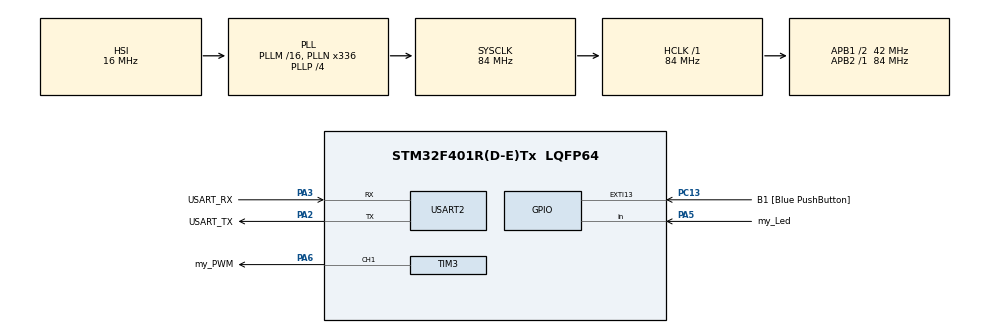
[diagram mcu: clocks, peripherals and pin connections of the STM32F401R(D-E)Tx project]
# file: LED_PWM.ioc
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Mcu.Family=STM32F4
Mcu.Name=STM32F401R(D-E)Tx
Mcu.Package=LQFP64
NVIC.PriorityGroup=NVIC_PRIORITYGROUP_0
PA13.GPIO_Label=TMS
PA13.Mode=Serial_Wire
PA13.Signal=SYS_JTMS-SWDIO
PA14.GPIO_Label=TCK
PA14.Mode=Serial_Wire
PA14.Signal=SYS_JTCK-SWCLK
PA2.GPIO_Label=USART_TX
PA2.GPIO_Mode=GPIO_MODE_AF_PP
PA2.GPIO_PuPd=GPIO_NOPULL
PA2.GPIO_Speed=GPIO_SPEED_FREQ_LOW
PA2.Mode=Asynchronous
PA2.Signal=USART2_TX
PA3.GPIO_Label=USART_RX
PA3.GPIO_Mode=GPIO_MODE_AF_PP
PA3.GPIO_PuPd=GPIO_NOPULL
PA3.GPIO_Speed=GPIO_SPEED_FREQ_LOW
PA3.Mode=Asynchronous
PA3.Signal=USART2_RX
PA5.GPIO_Label=my_Led
PA5.Signal=GPIO_Input
PA6.GPIO_Label=my_PWM
PA6.Signal=S_TIM3_CH1
PB3.GPIO_Label=SWO
PB3.Signal=SYS_JTDO-SWO
PC13-ANTI_TAMP.GPIO_Label=B1 [Blue PushButton]
PC13-ANTI_TAMP.GPIO_ModeDefaultEXTI=GPIO_MODE_IT_FALLING
PC13-ANTI_TAMP.GPIO_PuPd=GPIO_NOPULL
PC13-ANTI_TAMP.Signal=GPXTI13
PC14-OSC32_IN.Mode=LSE-External-Oscillator
PC14-OSC32_IN.Signal=RCC_OSC32_IN
PC15-OSC32_OUT.Mode=LSE-External-Oscillator
PC15-OSC32_OUT.Signal=RCC_OSC32_OUT
PH0\ -\ OSC_IN.Mode=HSE-External-Clock-Source
PH0\ -\ OSC_IN.Signal=RCC_OSC_IN
PH1\ -\ OSC_OUT.Mode=HSE-External-Clock-Source
PH1\ -\ OSC_OUT.Signal=RCC_OSC_OUT
ProjectManager.HeapSize=0x200
ProjectManager.StackSize=0x400
ProjectManager.TargetToolchain=SW4STM32
RCC.48MHZClocksFreq_Value=48000000
RCC.AHBFreq_Value=84000000
RCC.APB1CLKDivider=RCC_HCLK_DIV2
RCC.APB1Freq_Value=42000000
RCC.APB1TimFreq_Value=84000000
RCC.APB2Freq_Value=84000000
RCC.APB2TimFreq_Value=84000000
RCC.CortexFreq_Value=84000000
RCC.HCLKFreq_Value=84000000
RCC.HSE_VALUE=8000000
RCC.HSI_VALUE=16000000
RCC.PLLN=336
RCC.PLLP=RCC_PLLP_DIV4
RCC.PLLQ=7
RCC.SYSCLKFreq_VALUE=84000000
RCC.SYSCLKSource=RCC_SYSCLKSOURCE_PLLCLK
RCC.VCOOutputFreq_Value=336000000
SH.S_TIM3_CH1.0=TIM3_CH1,PWM Generation1 CH1
TIM3.Channel-PWM\ Generation1\ CH1=TIM_CHANNEL_1
TIM3.Period=100
TIM3.Prescaler=84
USART2.VirtualMode=VM_ASYNC
VP_TIM3_VS_ClockSourceINT.Mode=Internal
board=NUCLEO-F401RE

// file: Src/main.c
/**
  ******************************************************************************
  * @file           : main.c
  * @brief          : Main program body
  ******************************************************************************
  ** This notice applies to any and all portions of this file
  * that are not between comment pairs USER CODE BEGIN and
  * USER CODE END. Other portions of this file, whether
  * inserted by the user or by software development tools
  * are owned by their respective copyright owners.
  *
  * COPYRIGHT(c) 2018 STMicroelectronics
  *
  * Redistribution and use in source and binary forms, with or without modification,
  * are permitted provided that the following conditions are met:
  *   1. Redistributions of source code must retain the above copyright notice,
  *      this list of conditions and the following disclaimer.
  *   2. Redistributions in binary form must reproduce the above copyright notice,
  *      this list of conditions and the following disclaimer in the documentation
  *      and/or other materials provided with the distribution.
  *   3. Neither the name of STMicroelectronics nor the names of its contributors
  *      may be used to endorse or promote products derived from this software
  *      without specific prior written permission.
  *
  * THIS SOFTWARE IS PROVIDED BY THE COPYRIGHT HOLDERS AND CONTRIBUTORS "AS IS"
  * AND ANY EXPRESS OR IMPLIED WARRANTIES, INCLUDING, BUT NOT LIMITED TO, THE
  * IMPLIED WARRANTIES OF MERCHANTABILITY AND FITNESS FOR A PARTICULAR PURPOSE ARE
  * DISCLAIMED. IN NO EVENT SHALL THE COPYRIGHT HOLDER OR CONTRIBUTORS BE LIABLE
  * FOR ANY DIRECT, INDIRECT, INCIDENTAL, SPECIAL, EXEMPLARY, OR CONSEQUENTIAL
  * DAMAGES (INCLUDING, BUT NOT LIMITED TO, PROCUREMENT OF SUBSTITUTE GOODS OR
  * SERVICES; LOSS OF USE, DATA, OR PROFITS; OR BUSINESS INTERRUPTION) HOWEVER
  * CAUSED AND ON ANY THEORY OF LIABILITY, WHETHER IN CONTRACT, STRICT LIABILITY,
  * OR TORT (INCLUDING NEGLIGENCE OR OTHERWISE) ARISING IN ANY WAY OUT OF THE USE
  * OF THIS SOFTWARE, EVEN IF ADVISED OF THE POSSIBILITY OF SUCH DAMAGE.
  *
  ******************************************************************************
  */
#include "main.h"
#include "stm32f4xx_hal.h"

TIM_HandleTypeDef htim3;

UART_HandleTypeDef huart2;

/* USER CODE BEGIN PV */
/* Private variables ---------------------------------------------------------*/

/* USER CODE END PV */

void SystemClock_Config(void);
static void MX_GPIO_Init(void);
static void MX_USART2_UART_Init(void);
static void MX_TIM3_Init(void);
void HAL_TIM_MspPostInit(TIM_HandleTypeDef *htim);

/* USER CODE BEGIN PFP */
/* Private function prototypes -----------------------------------------------*/

/* USER CODE END PFP */

int main(void)
{

  /* MCU Configuration----------------------------------------------------------*/

  /* Reset of all peripherals, Initializes the Flash interface and the Systick. */
  HAL_Init();

  /* Configure the system clock */
  SystemClock_Config();

  /* Initialize all configured peripherals */
  MX_GPIO_Init();
  MX_USART2_UART_Init();
  MX_TIM3_Init();
  /* USER CODE BEGIN 2 */

  HAL_TIM_PWM_Start(&htim3, TIM_CHANNEL_1);

  /* USER CODE END 2 */

  /* Infinite loop */
  while (1)
  {

  /* USER CODE BEGIN 3 */

	  unsigned short int pwm = 0;
	  __HAL_TIM_SET_COMPARE(&htim3, TIM_CHANNEL_1, 10);
	  for(pwm = 0; pwm < (unsigned short int)(htim3.Instance->ARR & 0x0000FFFF); pwm++){
		  __HAL_TIM_SET_COMPARE(&htim3, TIM_CHANNEL_1, pwm);
		  HAL_Delay(10);
	  }
	  for(pwm = (unsigned short int)(htim3.Instance->ARR & 0x0000FFFF); pwm > 0; pwm--){
		  __HAL_TIM_SET_COMPARE(&htim3, TIM_CHANNEL_1, pwm);
		  HAL_Delay(10);
	  }

  }
  /* USER CODE END 3 */

}

void SystemClock_Config(void)
{

  RCC_OscInitTypeDef RCC_OscInitStruct;
  RCC_ClkInitTypeDef RCC_ClkInitStruct;

    /**Configure the main internal regulator output voltage
    */
  __HAL_RCC_PWR_CLK_ENABLE();

  __HAL_PWR_VOLTAGESCALING_CONFIG(PWR_REGULATOR_VOLTAGE_SCALE2);

    /**Initializes the CPU, AHB and APB busses clocks
    */
  RCC_OscInitStruct.OscillatorType = RCC_OSCILLATORTYPE_HSI;
  RCC_OscInitStruct.HSIState = RCC_HSI_ON;
  RCC_OscInitStruct.HSICalibrationValue = 16;
  RCC_OscInitStruct.PLL.PLLState = RCC_PLL_ON;
  RCC_OscInitStruct.PLL.PLLSource = RCC_PLLSOURCE_HSI;
  RCC_OscInitStruct.PLL.PLLM = 16;
  RCC_OscInitStruct.PLL.PLLN = 336;
  RCC_OscInitStruct.PLL.PLLP = RCC_PLLP_DIV4;
  RCC_OscInitStruct.PLL.PLLQ = 7;
  if (HAL_RCC_OscConfig(&RCC_OscInitStruct) != HAL_OK)
  {
    _Error_Handler(__FILE__, __LINE__);
  }

    /**Initializes the CPU, AHB and APB busses clocks
    */
  RCC_ClkInitStruct.ClockType = RCC_CLOCKTYPE_HCLK|RCC_CLOCKTYPE_SYSCLK
                              |RCC_CLOCKTYPE_PCLK1|RCC_CLOCKTYPE_PCLK2;
  RCC_ClkInitStruct.SYSCLKSource = RCC_SYSCLKSOURCE_PLLCLK;
  RCC_ClkInitStruct.AHBCLKDivider = RCC_SYSCLK_DIV1;
  RCC_ClkInitStruct.APB1CLKDivider = RCC_HCLK_DIV2;
  RCC_ClkInitStruct.APB2CLKDivider = RCC_HCLK_DIV1;

  if (HAL_RCC_ClockConfig(&RCC_ClkInitStruct, FLASH_LATENCY_2) != HAL_OK)
  {
    _Error_Handler(__FILE__, __LINE__);
  }

    /**Configure the Systick interrupt time
    */
  HAL_SYSTICK_Config(HAL_RCC_GetHCLKFreq()/1000);

    /**Configure the Systick
    */
  HAL_SYSTICK_CLKSourceConfig(SYSTICK_CLKSOURCE_HCLK);

  /* SysTick_IRQn interrupt configuration */
  HAL_NVIC_SetPriority(SysTick_IRQn, 0, 0);
}

/* TIM3 init function */
static void MX_TIM3_Init(void)
{

  TIM_ClockConfigTypeDef sClockSourceConfig;
  TIM_MasterConfigTypeDef sMasterConfig;
  TIM_OC_InitTypeDef sConfigOC;

  htim3.Instance = TIM3;
  htim3.Init.Prescaler = 84;
  htim3.Init.CounterMode = TIM_COUNTERMODE_UP;
  htim3.Init.Period = 100;
  htim3.Init.ClockDivision = TIM_CLOCKDIVISION_DIV1;
  if (HAL_TIM_Base_Init(&htim3) != HAL_OK)
  {
    _Error_Handler(__FILE__, __LINE__);
  }

  sClockSourceConfig.ClockSource = TIM_CLOCKSOURCE_INTERNAL;
  if (HAL_TIM_ConfigClockSource(&htim3, &sClockSourceConfig) != HAL_OK)
  {
    _Error_Handler(__FILE__, __LINE__);
  }

  if (HAL_TIM_PWM_Init(&htim3) != HAL_OK)
  {
    _Error_Handler(__FILE__, __LINE__);
  }

  sMasterConfig.MasterOutputTrigger = TIM_TRGO_RESET;
  sMasterConfig.MasterSlaveMode = TIM_MASTERSLAVEMODE_DISABLE;
  if (HAL_TIMEx_MasterConfigSynchronization(&htim3, &sMasterConfig) != HAL_OK)
  {
    _Error_Handler(__FILE__, __LINE__);
  }

  sConfigOC.OCMode = TIM_OCMODE_PWM1;
  sConfigOC.Pulse = 0;
  sConfigOC.OCPolarity = TIM_OCPOLARITY_HIGH;
  sConfigOC.OCFastMode = TIM_OCFAST_DISABLE;
  if (HAL_TIM_PWM_ConfigChannel(&htim3, &sConfigOC, TIM_CHANNEL_1) != HAL_OK)
  {
    _Error_Handler(__FILE__, __LINE__);
  }

  HAL_TIM_MspPostInit(&htim3);

}

/* USART2 init function */
static void MX_USART2_UART_Init(void)
{

  huart2.Instance = USART2;
  huart2.Init.BaudRate = 115200;
  huart2.Init.WordLength = UART_WORDLENGTH_8B;
  huart2.Init.StopBits = UART_STOPBITS_1;
  huart2.Init.Parity = UART_PARITY_NONE;
  huart2.Init.Mode = UART_MODE_TX_RX;
  huart2.Init.HwFlowCtl = UART_HWCONTROL_NONE;
  huart2.Init.OverSampling = UART_OVERSAMPLING_16;
  if (HAL_UART_Init(&huart2) != HAL_OK)
  {
    _Error_Handler(__FILE__, __LINE__);
  }

}

/** Configure pins as
        * Analog
        * Input
        * Output
        * EVENT_OUT
        * EXTI
*/
static void MX_GPIO_Init(void)
{

  GPIO_InitTypeDef GPIO_InitStruct;

  /* GPIO Ports Clock Enable */
  __HAL_RCC_GPIOC_CLK_ENABLE();
  __HAL_RCC_GPIOH_CLK_ENABLE();
  __HAL_RCC_GPIOA_CLK_ENABLE();
  __HAL_RCC_GPIOB_CLK_ENABLE();

  /*Configure GPIO pin : B1_Pin */
  GPIO_InitStruct.Pin = B1_Pin;
  GPIO_InitStruct.Mode = GPIO_MODE_IT_FALLING;
  GPIO_InitStruct.Pull = GPIO_NOPULL;
  HAL_GPIO_Init(B1_GPIO_Port, &GPIO_InitStruct);

  /*Configure GPIO pin : my_Led_Pin */
  GPIO_InitStruct.Pin = my_Led_Pin;
  GPIO_InitStruct.Mode = GPIO_MODE_INPUT;
  GPIO_InitStruct.Pull = GPIO_NOPULL;
  HAL_GPIO_Init(my_Led_GPIO_Port, &GPIO_InitStruct);

}

void _Error_Handler(char *file, int line)
{
  while(1)
  {
  }
}

/************************ (C) COPYRIGHT STMicroelectronics *****END OF FILE****/
